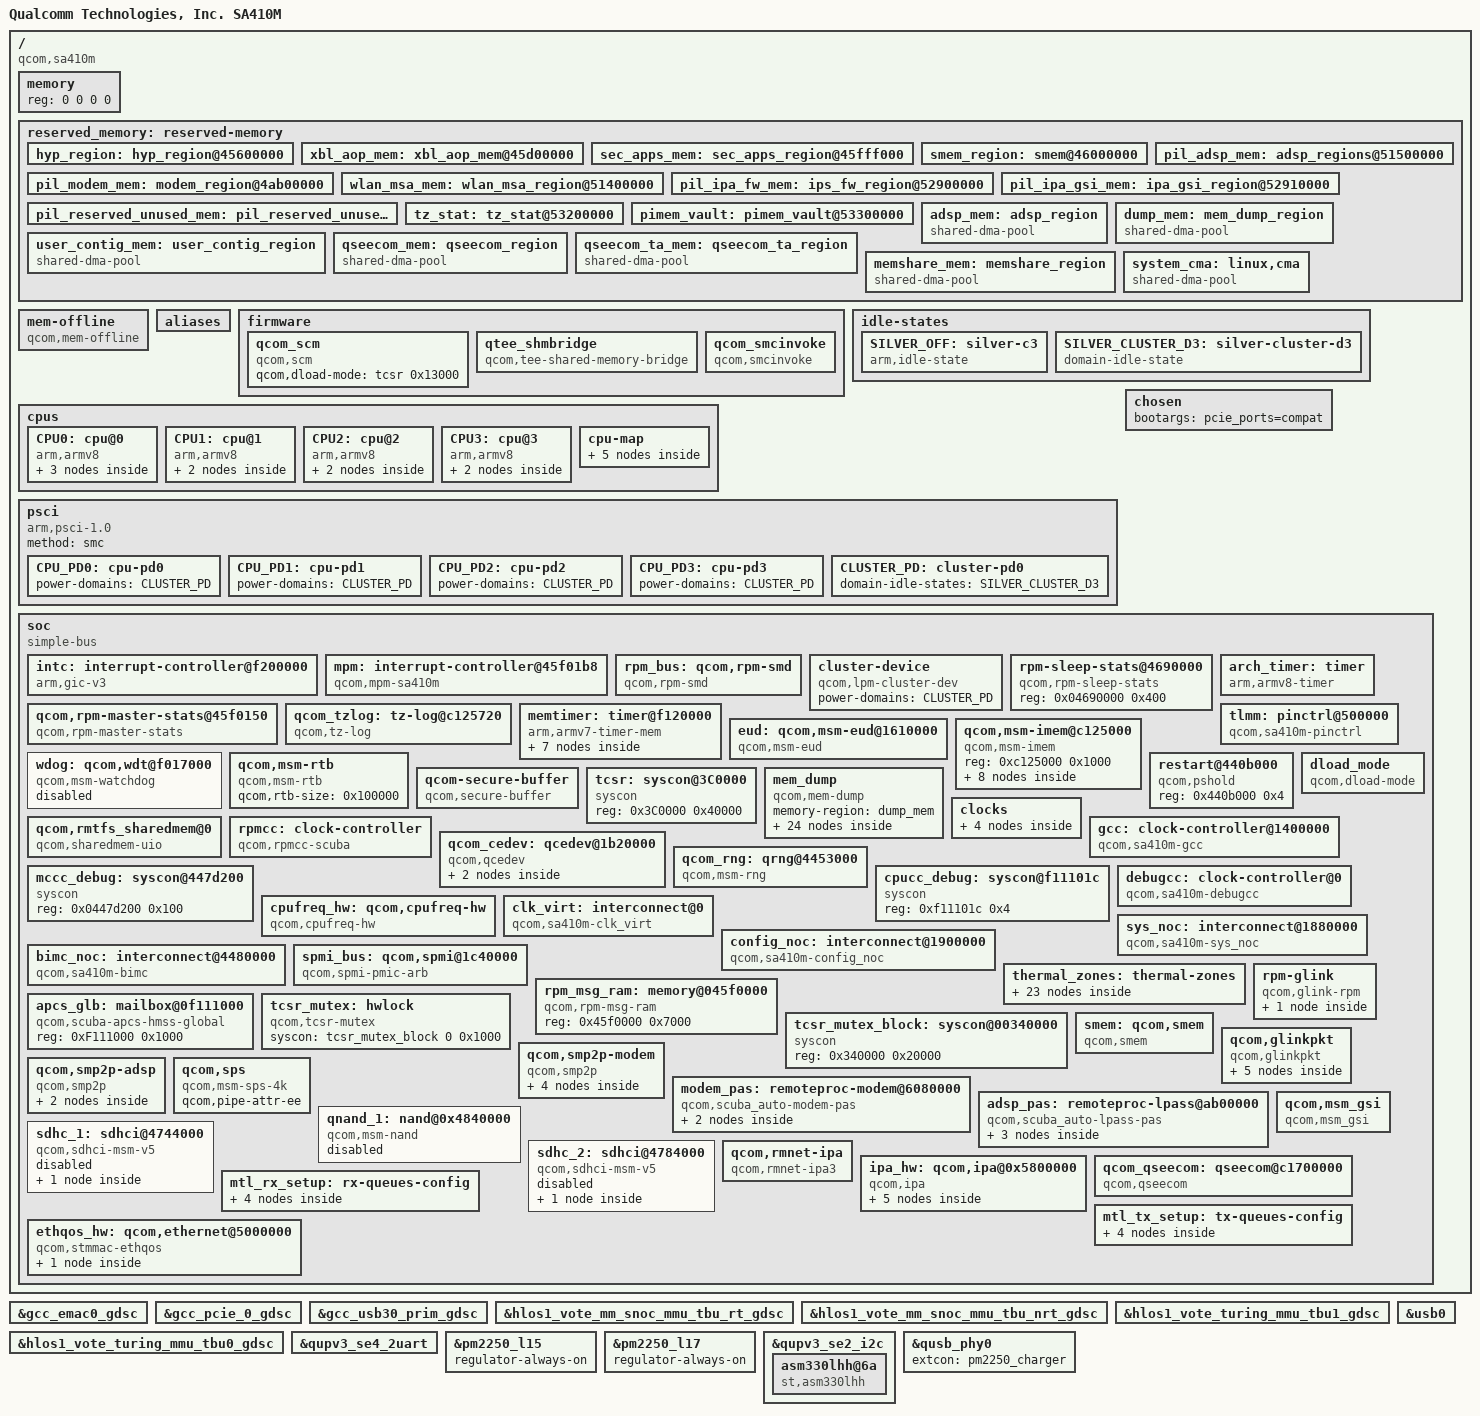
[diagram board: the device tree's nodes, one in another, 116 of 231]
#include <dt-bindings/interconnect/qcom,icc.h>
#include <dt-bindings/interconnect/qcom,sa410m.h>
#include <dt-bindings/interrupt-controller/arm-gic.h>
#include <dt-bindings/gpio/gpio.h>
#include <dt-bindings/clock/qcom,gcc-sa410m.h>
#include <dt-bindings/clock/qcom,rpmcc.h>
#include <dt-bindings/regulator/qcom,rpmh-regulator-levels.h>

/ {
	model = "Qualcomm Technologies, Inc. SA410M";
	compatible = "qcom,sa410m";
	qcom,msm-id = <560 0x10000>;
	interrupt-parent = <&intc>;

	#address-cells = <2>;
	#size-cells = <2>;
	memory { device_type = "memory"; reg = <0 0 0 0>; };

	reserved_memory: reserved-memory { };

	mem-offline {
		compatible = "qcom,mem-offline";
		offline-sizes = <0x1 0x40000000 0x0 0x40000000>,
				<0x1 0xc0000000 0x0 0x80000000>,
				<0x2 0xc0000000 0x1 0x40000000>;
		granule = <512>;
	};

	aliases: aliases {
		serial0 = &qupv3_se4_2uart;
		qpic_nand1 = &qnand_1;
		mmc0 = &sdhc_1; /*SDC1 eMMC slot*/
		mmc1 = &sdhc_2; /* SDC2 SD card slot */
		pci-domain0 = &pcie0;
	};

	firmware: firmware {};

	cpus {
		#address-cells = <2>;
		#size-cells = <0>;

		CPU0: cpu@0 {
			device_type = "cpu";
			compatible = "arm,armv8";
			reg = <0x0 0x0>;
			cpu-idle-states = <&SILVER_OFF>;
			power-domains = <&CPU_PD0>;
			power-domain-names = "psci";
			enable-method = "psci";
			capacity-dmips-mhz = <1024>;
			dynamic-power-coefficient = <100>;
			next-level-cache = <&L2_0>;
			qcom,freq-domain = <&cpufreq_hw 0>;
			qcom,lmh-dcvs = <&lmh_dcvs0>;
			#cooling-cells = <2>;
			L2_0: l2-cache {
				compatible = "arm,arch-cache";
				cache-level = <2>;
			};

			L1_I_0: l1-icache {
				compatible = "arm,arch-cache";
			};

			L1_D_0: l1-dcache {
				compatible = "arm,arch-cache";
			};
		};

		CPU1: cpu@1 {
			device_type = "cpu";
			compatible = "arm,armv8";
			reg = <0x0 0x1>;
			cpu-idle-states = <&SILVER_OFF>;
			power-domains = <&CPU_PD1>;
			power-domain-names = "psci";
			enable-method = "psci";
			capacity-dmips-mhz = <1024>;
			dynamic-power-coefficient = <100>;
			next-level-cache = <&L2_0>;
			qcom,freq-domain = <&cpufreq_hw 0>;
			qcom,lmh-dcvs = <&lmh_dcvs0>;
			#cooling-cells = <2>;

			L1_I_1: l1-icache {
				compatible = "arm,arch-cache";
			};

			L1_D_1: l1-dcache {
				compatible = "arm,arch-cache";
			};
		};

		CPU2: cpu@2 {
			device_type = "cpu";
			compatible = "arm,armv8";
			reg = <0x0 0x2>;
			cpu-idle-states = <&SILVER_OFF>;
			power-domains = <&CPU_PD2>;
			power-domain-names = "psci";
			enable-method = "psci";
			capacity-dmips-mhz = <1024>;
			dynamic-power-coefficient = <100>;
			next-level-cache = <&L2_0>;
			qcom,freq-domain = <&cpufreq_hw 0>;
			qcom,lmh-dcvs = <&lmh_dcvs0>;
			#cooling-cells = <2>;

			L1_I_2: l1-icache {
				compatible = "arm,arch-cache";
			};

			L1_D_2: l1-dcache {
				compatible = "arm,arch-cache";
			};
		};

		CPU3: cpu@3 {
			device_type = "cpu";
			compatible = "arm,armv8";
			reg = <0x0 0x3>;
			cpu-idle-states = <&SILVER_OFF>;
			power-domains = <&CPU_PD3>;
			power-domain-names = "psci";
			enable-method = "psci";
			capacity-dmips-mhz = <1024>;
			dynamic-power-coefficient = <100>;
			next-level-cache = <&L2_0>;
			qcom,freq-domain = <&cpufreq_hw 0>;
			qcom,lmh-dcvs = <&lmh_dcvs0>;
			#cooling-cells = <2>;

			L1_I_3: l1-icache {
				compatible = "arm,arch-cache";
			};

			L1_D_3: l1-dcache {
				compatible = "arm,arch-cache";
			};
		};

		cpu-map {
			cluster0 {
				core0 {
					cpu = <&CPU0>;
				};

				core1 {
					cpu = <&CPU1>;
				};

				core2 {
					cpu = <&CPU2>;
				};

				core3 {
					cpu = <&CPU3>;
				};
			};
		};
	};

	idle-states {
		SILVER_OFF: silver-c3 {  /* C3 */
			compatible = "arm,idle-state";
			idle-state-name = "pc";
			entry-latency-us = <297>;
			exit-latency-us = <324>;
			min-residency-us = <1110>;
			arm,psci-suspend-param = <0x40000003>;
			local-timer-stop;
		};

		SILVER_CLUSTER_D3: silver-cluster-d3 { /* D3 */
			compatible = "domain-idle-state";
			idle-state-name = "pwr-l2-pc";
			entry-latency-us = <800>;
			exit-latency-us = <2118>;
			min-residency-us = <7376>;
			arm,psci-suspend-param = <0x41000043>;
		};
	};

	psci {
		compatible = "arm,psci-1.0";
		method = "smc";

		CPU_PD0: cpu-pd0 {
			#power-domain-cells = <0>;
			power-domains = <&CLUSTER_PD>;
		};

		CPU_PD1: cpu-pd1 {
			#power-domain-cells = <0>;
			power-domains = <&CLUSTER_PD>;
		};

		CPU_PD2: cpu-pd2 {
			#power-domain-cells = <0>;
			power-domains = <&CLUSTER_PD>;
		};

		CPU_PD3: cpu-pd3 {
			#power-domain-cells = <0>;
			power-domains = <&CLUSTER_PD>;
		};

		CLUSTER_PD: cluster-pd0 {
			#power-domain-cells = <0>;
			domain-idle-states = <&SILVER_CLUSTER_D3>;
		};
	};

	chosen {
		bootargs = "pcie_ports=compat";
	};

	soc: soc { };
};

&reserved_memory {
	#address-cells = <2>;
	#size-cells = <2>;
	ranges;

	hyp_region: hyp_region@45600000 {
		no-map;
		reg = <0x0 0x45600000 0x0 0x700000>;
	};

	xbl_aop_mem: xbl_aop_mem@45d00000 {
		no-map;
		reg = <0x0 0x45d00000 0x0 0x200000>;
	};

	sec_apps_mem: sec_apps_region@45fff000 {
		no-map;
		reg = <0x0 0x45fff000 0x0 0x1000>;
	};

	smem_region: smem@46000000 {
		no-map;
		reg = <0x0 0x46000000 0x0 0x200000>;
	};

	pil_modem_mem: modem_region@4ab00000 {
		no-map;
		reg = <0x0 0x4ab00000 0x0 0x6900000>;
	};

	wlan_msa_mem: wlan_msa_region@51400000 {
		no-map;
		reg = <0x0 0x51400000 0x0 0x100000>;
	};

	pil_adsp_mem: adsp_regions@51500000 {
		no-map;
		reg = <0x0 0x51500000 0x0 0x1400000>;
	};

	pil_ipa_fw_mem: ips_fw_region@52900000 {
		no-map;
		reg = <0x0 0x52900000 0x0 0x10000>;
	};

	pil_ipa_gsi_mem: ipa_gsi_region@52910000 {
		no-map;
		reg = <0x0 0x52910000 0x0 0x5000>;
	};

	pil_reserved_unused_mem: pil_reserved_unused_region@52915000 {
		no-map;
		reg = <0x0 0x52915000 0x0 0xEB000>;
	};

	tz_stat: tz_stat@53200000 {
		no-map;
		reg = <0x0 0x53200000 0x0 0x100000>;
	};

	pimem_vault: pimem_vault@53300000 {
		no-map;
		reg = <0x0 0x53300000 0x0 0x1500000>;
	};

	adsp_mem: adsp_region {
		compatible = "shared-dma-pool";
		alloc-ranges = <0 0x00000000 0 0xffffffff>;
		reusable;
		alignment = <0 0x400000>;
		size = <0 0x800000>;
	};

	dump_mem: mem_dump_region {
		compatible = "shared-dma-pool";
		alloc-ranges = <0x0 0x00000000 0x0 0xffffffff>;
		reusable;
		size = <0 0x800000>;
	};

	user_contig_mem: user_contig_region {
		compatible = "shared-dma-pool";
		alloc-ranges = <0x0 0x00000000 0x0 0xffffffff>;
		reusable;
		alignment = <0x0 0x400000>;
		size = <0x0 0x1000000>;
	};

	qseecom_mem: qseecom_region {
		compatible = "shared-dma-pool";
		alloc-ranges = <0x0 0x00000000 0x0 0xffffffff>;
		reusable;
		alignment = <0x0 0x400000>;
		size = <0x0 0x800000>;
	};

	qseecom_ta_mem: qseecom_ta_region {
		compatible = "shared-dma-pool";
		alloc-ranges = <0x0 0x00000000 0x0 0xffffffff>;
		reusable;
		alignment = <0x0 0x400000>;
		size = <0x0 0x400000>;
	};

	memshare_mem: memshare_region {
		compatible = "shared-dma-pool";
		no-map;
		alloc-ranges = <0x0 0x00000000 0x0 0xffffffff>;
		alignment = <0x0 0x100000>;
		size = <0x0 0x800000>;
	};

	/* global autoconfigured region for contiguous allocations */
	system_cma:linux,cma {
		compatible = "shared-dma-pool";
		alloc-ranges = <0x0 0x00000000 0x0 0xffffffff>;
		reusable;
		alignment = <0x0 0x400000>;
		size = <0x0 0x2000000>;
		linux,cma-default;
	};
};

&soc {
	#address-cells = <1>;
	#size-cells = <1>;
	ranges = <0 0 0 0xffffffff>;
	compatible = "simple-bus";

	intc: interrupt-controller@f200000 {
		compatible = "arm,gic-v3";
		#interrupt-cells = <3>;
		interrupt-controller;
		interrupt-parent = <&intc>;
		#redistributor-regions = <1>;
		redistributor-stride = <0x0 0x20000>;
		reg = <0xf200000 0x10000>,	 /* GICD */
			  <0xf300000 0x100000>;	/* GICR * 8 */
		interrupts = <GIC_PPI 9 IRQ_TYPE_LEVEL_HIGH>;
		#gpio-cells = <0>;
	};

	mpm: interrupt-controller@45f01b8 {
		compatible = "qcom,mpm-sa410m", "qcom,mpm";
		reg = <0x45f01b8 0x1000>,
		      <0xf111008 0x4>,  /* MSM_APCS_GCC_BASE 4K */
		      <0xf121000 0x1000>;
		reg-names = "vmpm", "ipc", "timer";
		interrupts = <GIC_SPI 197 IRQ_TYPE_EDGE_RISING>;
		qcom,num-mpm-irqs = <96>;
		interrupt-controller;
		interrupt-parent = <&intc>;
		#interrupt-cells = <2>;
	};

	rpm_bus: qcom,rpm-smd {
		compatible = "qcom,rpm-smd";
		rpm-channel-name = "rpm_requests";
		interrupts = <GIC_SPI 194 IRQ_TYPE_EDGE_RISING>;
		power-domains = <&CLUSTER_PD>;
		rpm-channel-type = <15>; /* SMD_APPS_RPM */
	};

	cluster-device {
		compatible = "qcom,lpm-cluster-dev";
		power-domains = <&CLUSTER_PD>;
	};

	rpm-sleep-stats@4690000 {
		compatible = "qcom,rpm-sleep-stats";
		reg = <0x04690000 0x400>;
	};

	qcom,rpm-master-stats@45f0150 {
		compatible = "qcom,rpm-master-stats";
		reg = <0x45f0150 0x5000>;
		qcom,masters = "APSS", "MPSS", "ADSP", "CDSP", "TZ";
		qcom,master-stats-version = <2>;
		qcom,master-offset = <4096>;
	};

	arch_timer: timer {
		compatible = "arm,armv8-timer";
		interrupts = <GIC_PPI 1 (GIC_CPU_MASK_SIMPLE(8) | IRQ_TYPE_LEVEL_LOW)>,
				 <GIC_PPI 2 (GIC_CPU_MASK_SIMPLE(8) | IRQ_TYPE_LEVEL_LOW)>,
				 <GIC_PPI 3 (GIC_CPU_MASK_SIMPLE(8) | IRQ_TYPE_LEVEL_LOW)>,
				 <GIC_PPI 0 (GIC_CPU_MASK_SIMPLE(8) | IRQ_TYPE_LEVEL_LOW)>;
		clock-frequency = <19200000>;
	};

	qcom_tzlog: tz-log@c125720 {
		compatible = "qcom,tz-log";
		reg = <0xc125720 0x3000>;
		qcom,hyplog-enabled;
		hyplog-address-offset = <0x410>;
		hyplog-size-offset = <0x414>;
	};

	memtimer: timer@f120000 {
		#address-cells = <1>;
		#size-cells = <1>;
		ranges;
		compatible = "arm,armv7-timer-mem";
		reg = <0xf120000 0x1000>;
		clock-frequency = <19200000>;

		frame@f121000 {
			frame-number = <0>;
			interrupts = <GIC_SPI 8 IRQ_TYPE_LEVEL_HIGH>,
					 <GIC_SPI 7 IRQ_TYPE_LEVEL_HIGH>;
			reg = <0xf121000 0x1000>,
				  <0xf122000 0x1000>;
		};

		frame@f123000 {
			frame-number = <1>;
			interrupts = <GIC_SPI 9 IRQ_TYPE_LEVEL_HIGH>;
			reg = <0xf123000 0x1000>;
			status = "disabled";
		};

		frame@f124000 {
			frame-number = <2>;
			interrupts = <GIC_SPI 10 IRQ_TYPE_LEVEL_HIGH>;
			reg = <0xf124000 0x1000>;
			status = "disabled";
		};

		frame@f125000 {
			frame-number = <3>;
			interrupts = <GIC_SPI 11 IRQ_TYPE_LEVEL_HIGH>;
			reg = <0xf125000 0x1000>;
			status = "disabled";
		};

		frame@f126000 {
			frame-number = <4>;
			interrupts = <GIC_SPI 12 IRQ_TYPE_LEVEL_HIGH>;
			reg = <0xf126000 0x1000>;
			status = "disabled";
		};

		frame@f127000 {
			frame-number = <5>;
			interrupts = <GIC_SPI 13 IRQ_TYPE_LEVEL_HIGH>;
			reg = <0xf127000 0x1000>;
			status = "disabled";
		};

		frame@f128000 {
			frame-number = <6>;
			interrupts = <GIC_SPI 14 IRQ_TYPE_LEVEL_HIGH>;
			reg = <0xf128000 0x1000>;
			status = "disabled";
		};
	};

	tlmm: pinctrl@500000 {
			compatible = "qcom,sa410m-pinctrl";
			reg = <0x500000 0x7F000>,
				<0x598000 0xD000>;
			reg-names = "normal" , "extended";
			interrupts = <GIC_SPI 227 IRQ_TYPE_LEVEL_HIGH>;
			gpio-ranges = <&tlmm 0 0 139>;
			gpio-controller;
			#gpio-cells = <2>;
			wakeup-parent = <&mpm>;
			interrupt-controller;
			#interrupt-cells = <2>;
	};

	eud: qcom,msm-eud@1610000 {
		compatible = "qcom,msm-eud";
		interrupt-names = "eud_irq";
		interrupts = <GIC_SPI 189 IRQ_TYPE_LEVEL_HIGH>;
		reg = <0x1610000 0x2000>,
		      <0x1612000 0x1000>,
		      <0x3E5018 0x4>;
		reg-names = "eud_base", "eud_mode_mgr2",
				"eud_tcsr_check_reg";
		qcom,secure-eud-en;
		qcom,eud-tcsr-check-enable;
		qcom,eud-clock-vote-req;
		clocks = <&gcc GCC_AHB2PHY_USB_CLK>;
		clock-names = "eud_ahb2phy_clk";
		status = "ok";
	};

	qcom,msm-imem@c125000 {
		compatible = "qcom,msm-imem";
		reg = <0xc125000 0x1000>;
		ranges = <0x0 0xc125000 0x1000>;
		#address-cells = <1>;
		#size-cells = <1>;

		mem_dump_table@10 {
			compatible = "qcom,msm-imem-mem_dump_table";
			reg = <0x10 0x8>;
		};

		dload_type@1c {
			compatible = "qcom,msm-imem-dload-type";
			reg = <0x1c 0x4>;
		};

		restart_reason@65c {
			compatible = "qcom,msm-imem-restart_reason";
			reg = <0x65c 0x4>;
		};

		boot_stats@6b0 {
			compatible = "qcom,msm-imem-boot_stats";
			reg = <0x6b0 0x20>;
		};

		kaslr_offset@6d0 {
			compatible = "qcom,msm-imem-kaslr_offset";
			reg = <0x6d0 0xc>;
		};

		pil@94c {
			compatible = "qcom,pil-reloc-info";
			reg = <0x94c 0xc8>;
		};

		pil@6dc {
			compatible = "qcom,msm-imem-pil-disable-timeout";
			reg = <0x6dc 0x4>;
		};

		diag_dload@c8 {
			compatible = "qcom,msm-imem-diag-dload";
			reg = <0xc8 0xc8>;
		};
	};

	wdog: qcom,wdt@f017000 {
		compatible = "qcom,msm-watchdog";
		reg = <0xf017000 0x1000>;
		reg-names = "wdt-base";
		interrupts = <GIC_SPI 3 IRQ_TYPE_EDGE_RISING>,
				<GIC_SPI 4 IRQ_TYPE_LEVEL_HIGH>;
		status="disabled";
	};

	qcom,msm-rtb {
		compatible = "qcom,msm-rtb";
		qcom,rtb-size = <0x100000>;
	};

	restart@440b000 {
		compatible = "qcom,pshold";
		reg = <0x440b000 0x4>;
	};

	dload_mode {
		compatible = "qcom,dload-mode";
	};

	qcom-secure-buffer {
		compatible = "qcom,secure-buffer";
	};

	tcsr: syscon@3C0000 {
		compatible = "syscon";
		reg = <0x3C0000 0x40000>;
	};

	mem_dump {
		compatible = "qcom,mem-dump";
		memory-region = <&dump_mem>;

		c0_context {
			qcom,dump-size = <0x800>;
			qcom,dump-id = <0x0>;
		};

		c1_context {
			qcom,dump-size = <0x800>;
			qcom,dump-id = <0x1>;
		};

		c2_context {
			qcom,dump-size = <0x800>;
			qcom,dump-id = <0x2>;
		};

		c3_context {
			qcom,dump-size = <0x800>;
			qcom,dump-id = <0x3>;
		};

		l1_icache0 {
			qcom,dump-size = <0x9040>;
			qcom,dump-id = <0x60>;
		};

		l1_icache1 {
			qcom,dump-size = <0x9040>;
			qcom,dump-id = <0x61>;
		};

		l1_icache2 {
			qcom,dump-size = <0x9040>;
			qcom,dump-id = <0x62>;
		};

		l1_icache3 {
			qcom,dump-size = <0x9040>;
			qcom,dump-id = <0x63>;
		};

		l1_dcache0 {
			qcom,dump-size = <0x9040>;
			qcom,dump-id = <0x80>;
		};

		l1_dcache1 {
			qcom,dump-size = <0x9040>;
			qcom,dump-id = <0x81>;
		};

		l1_dcache2 {
			qcom,dump-size = <0x9040>;
			qcom,dump-id = <0x82>;
		};

		l1_dcache3 {
			qcom,dump-size = <0x9040>;
			qcom,dump-id = <0x83>;
		};

		l2_tlb0 {
			qcom,dump-size = <0x2000>;
			qcom,dump-id = <0x120>;
		};

		l2_tlb1 {
			qcom,dump-size = <0x2000>;
			qcom,dump-id = <0x121>;
		};

		l2_tlb2 {
			qcom,dump-size = <0x2000>;
			qcom,dump-id = <0x122>;
		};

		l2_tlb3 {
			qcom,dump-size = <0x2000>;
			qcom,dump-id = <0x123>;
		};

		spm_reg {
			qcom,dump-size = <0x400>;
			qcom,dump-id = <0x164>;
		};

		rpm_sw {
			qcom,dump-size = <0x28000>;
			qcom,dump-id = <0xea>;
		};

		pmic {
			qcom,dump-size = <0x40000>;
			qcom,dump-id = <0xe4>;
		};

		fcm {
			qcom,dump-size = <0x8400>;
			qcom,dump-id = <0xee>;
		};

		tmc_etf {
			qcom,dump-size = <0x8000>;
			qcom,dump-id = <0xf0>;
		};

		etr_reg {
			qcom,dump-size = <0x1000>;
			qcom,dump-id = <0x100>;
		};

		etf_reg {
			qcom,dump-size = <0x1000>;
			qcom,dump-id = <0x101>;
		};

		misc_data {
			qcom,dump-size = <0x1000>;
			qcom,dump-id = <0xe8>;
		};
	};

	qcom,rmtfs_sharedmem@0 {
		compatible = "qcom,sharedmem-uio";
		reg = <0x0 0x280000>;
		reg-names = "rmtfs";
		qcom,client-id = <0x00000001>;
		qcom,vm-nav-path;
	};

	clocks {
		xo_board: xo-board {
			compatible = "fixed-clock";
			clock-frequency = <38400000>;
			clock-output-names = "xo_board";
			#clock-cells = <0>;
		};

		sleep_clk: sleep-clk {
			compatible = "fixed-clock";
			clock-frequency = <32000>;
			clock-output-names = "chip_sleep_clk";
			#clock-cells = <0>;
		};

		pcie_0_pipe_clk: pcie_0_pipe_clk {
			compatible = "fixed-clock";
			clock-frequency = <1000>;
			clock-output-names = "pcie_0_pipe_clk";
			#clock-cells = <0>;
		};

		usb3_phy_wrapper_gcc_usb30_pipe_clk: usb3_phy_wrapper_gcc_usb30_pipe_clk {
			compatible = "fixed-clock";
			clock-frequency = <1000>;
			clock-output-names = "usb3_phy_wrapper_gcc_usb30_pipe_clk";
			#clock-cells = <0>;
		};
	};

	rpmcc: clock-controller {
		compatible = "qcom,rpmcc-scuba";
		#clock-cells = <1>;
	};

	gcc: clock-controller@1400000 {
		compatible = "qcom,sa410m-gcc", "syscon";
		reg = <0x1400000 0x1f0000>;
		reg-name = "cc_base";
		vdd_cx-supply = <&VDD_CX_LEVEL>;
		clocks = <&rpmcc RPM_SMD_XO_CLK_SRC>,
			 <&rpmcc RPM_SMD_XO_A_CLK_SRC>,
			<&pcie_0_pipe_clk>,
			<&sleep_clk>,
			<&usb3_phy_wrapper_gcc_usb30_pipe_clk>;
		clock-names = "bi_tcxo",
			"bi_tcxo_ao",
			"pcie_0_pipe_clk",
			"sleep_clk",
			"usb3_phy_wrapper_gcc_usb30_pipe_clk";
		#clock-cells = <1>;
		#reset-cells = <1>;
	};

	qcom_cedev: qcedev@1b20000 {
		compatible = "qcom,qcedev";
		reg = <0x1b20000 0x20000>,
			<0x1b04000 0x24000>;
		reg-names = "crypto-base","crypto-bam-base";
		interrupts = <GIC_SPI 247 IRQ_TYPE_LEVEL_HIGH>;
		qcom,bam-pipe-pair = <2>;
		qcom,ce-hw-instance = <0>;
		qcom,ce-device = <0>;
		qcom,ce-hw-shared;
		qcom,bam-ee = <0>;
		qcom,smmu-s1-enable;
		qcom,no-clock-support;
		interconnect-names = "data_path";
		interconnects = <&sys_noc MASTER_CRYPTO_CORE0 &bimc_noc SLAVE_EBI_CH0>;
		iommus = <&apps_smmu 0x0084 0x0011>,
				<&apps_smmu 0x0092 0x00>,
				<&apps_smmu 0x0086 0x0011>;
		qcom,iommu-dma = "atomic";
		dma-coherent;

		qcom_cedev_ns_cb {
			compatible = "qcom,qcedev,context-bank";
			label = "ns_context";
			iommus = <&apps_smmu 0x0086 0x0011>,
				<&apps_smmu 0x0092 0x00>,
				<&apps_smmu 0x0098 0x0001>;
			dma-coherent;
		};

		qcom_cedev_s_cb {
			compatible = "qcom,qcedev,context-bank";
			label = "secure_context";
			iommus = <&apps_smmu 0x093 0x000>,
				 <&apps_smmu 0x09c 0x001>,
				 <&apps_smmu 0x09d 0x001>,
				 <&apps_smmu 0x09E 0x000>;
			qcom,iommu-vmid = <0x9>;
			qcom,secure-context-bank;
		};
	};

	qcom_rng: qrng@4453000 {
		compatible = "qcom,msm-rng";
		reg = <0x4453000 0x1000>;
		qcom,no-qrng-config;
		qcom,no-clock-support;
	};

	mccc_debug: syscon@447d200 {
		compatible = "syscon";
		reg = <0x0447d200 0x100>;
	};

	cpucc_debug: syscon@f11101c {
		compatible = "syscon";
		reg = <0xf11101c 0x4>;
	};

	debugcc: clock-controller@0 {
		compatible = "qcom,sa410m-debugcc";
		qcom,gcc = <&gcc>;
		qcom,mccc = <&mccc_debug>;
		qcom,cpucc = <&cpucc_debug>;
		clock-names = "xo_clk_src";
		clocks = <&rpmcc RPM_SMD_XO_CLK_SRC>, <&gcc 0>;
		#clock-cells = <1>;
	};

	cpufreq_hw: qcom,cpufreq-hw {
		compatible = "qcom,cpufreq-hw";
		reg = <0xf521000 0x1400>;
		reg-names = "freq-domain0";
		clocks = <&rpmcc RPM_SMD_XO_CLK_SRC>, <&gcc GPLL0>;
		clock-names = "xo", "alternate";
		#freq-domain-cells = <1>;
	};

	clk_virt: interconnect@0 {
		compatible = "qcom,sa410m-clk_virt";
		qcom,keepalive;
		#interconnect-cells = <1>;
		clock-names = "bus", "bus_a";
		clocks = <&rpmcc RPM_SMD_QUP_CLK>,
			<&rpmcc RPM_SMD_QUP_A_CLK>;
	};

	sys_noc: interconnect@1880000 {
		reg = <0x1880000 0x5e080>;
		compatible = "qcom,sa410m-sys_noc";
		qcom,keepalive;
		#interconnect-cells = <1>;
		clock-names = "bus", "bus_a";
		clocks = <&rpmcc RPM_SMD_SNOC_CLK>,
			<&rpmcc RPM_SMD_SNOC_A_CLK>;
	};

	config_noc: interconnect@1900000 {
		reg = <0x01900000 0x9200>;
		compatible = "qcom,sa410m-config_noc";
		qcom,keepalive;
		#interconnect-cells = <1>;
		clock-names = "bus", "bus_a";
		clocks = <&rpmcc RPM_SMD_CNOC_CLK>,
			<&rpmcc RPM_SMD_CNOC_A_CLK>;
	};

	bimc_noc: interconnect@4480000 {
		reg = <0x4480000 0x80000>;
		compatible = "qcom,sa410m-bimc";
		qcom,util-factor = <153>;
		qcom,keepalive;
		#interconnect-cells = <1>;
		clock-names = "bus", "bus_a";
		clocks = <&rpmcc RPM_SMD_BIMC_CLK>,
			<&rpmcc RPM_SMD_BIMC_A_CLK>;
	};

	spmi_bus: qcom,spmi@1c40000 {
		compatible = "qcom,spmi-pmic-arb";
		reg = <0x1c40000 0x1100>,
			<0x1e00000 0x2000000>,
			<0x3e00000 0x100000>,
			<0x3f00000 0xa0000>,
			<0x1c0a000 0x26000>;
		reg-names = "core", "chnls", "obsrvr", "intr", "cnfg";
		interrupt-names = "periph_irq";
		interrupts-extended = <&mpm 86 IRQ_TYPE_LEVEL_HIGH>;
		qcom,ee = <0>;
		qcom,channel = <0>;
		#address-cells = <2>;
		#size-cells = <0>;
		interrupt-controller;
		#interrupt-cells = <4>;
		cell-index = <0>;
	};

	thermal_zones: thermal-zones { };

	rpm_msg_ram: memory@045f0000 {
		compatible = "qcom,rpm-msg-ram";
		reg = <0x45f0000 0x7000>;
	};

	apcs_glb: mailbox@0f111000 {
		compatible = "qcom,scuba-apcs-hmss-global";
		reg = <0xF111000 0x1000>;

		#mbox-cells = <1>;
	};

	rpm-glink {
		compatible = "qcom,glink-rpm";
		interrupts = <GIC_SPI 194 IRQ_TYPE_EDGE_RISING>;
		qcom,rpm-msg-ram = <&rpm_msg_ram>;
		mboxes = <&apcs_glb 0>;

		qcom,rpm_glink_ssr {
			qcom,glink-channels = "glink_ssr";
			// qcom,notify-edges = <&glink_adsp>;
		};
	};

	tcsr_mutex_block: syscon@00340000 {
		compatible = "syscon";
		reg = <0x340000 0x20000>;
	};

	tcsr_mutex: hwlock {
		compatible = "qcom,tcsr-mutex";
		syscon = <&tcsr_mutex_block 0 0x1000>;
		#hwlock-cells = <1>;
	};

	smem: qcom,smem {
		compatible = "qcom,smem";
		memory-region = <&smem_region>;
		hwlocks = <&tcsr_mutex 3>;
	};

	qcom,glinkpkt {
		compatible = "qcom,glinkpkt";

		qcom,glinkpkt-at-mdm0 {
			qcom,glinkpkt-edge = "mpss";
			qcom,glinkpkt-ch-name = "DS";
			qcom,glinkpkt-dev-name = "at_mdm0";
		};

		qcom,glinkpkt-data40-cntl {
			qcom,glinkpkt-edge = "mpss";
			qcom,glinkpkt-ch-name = "DATA40_CNTL";
			qcom,glinkpkt-dev-name = "smdcntl8";
		};

		qcom,glinkpkt-data1 {
			qcom,glinkpkt-edge = "mpss";
			qcom,glinkpkt-ch-name = "DATA1";
			qcom,glinkpkt-dev-name = "smd7";
		};

		qcom,glinkpkt-data4 {
			qcom,glinkpkt-edge = "mpss";
			qcom,glinkpkt-ch-name = "DATA4";
			qcom,glinkpkt-dev-name = "smd8";
		};

		qcom,glinkpkt-data11 {
			qcom,glinkpkt-edge = "mpss";
			qcom,glinkpkt-ch-name = "DATA11";
			qcom,glinkpkt-dev-name = "smd11";
		};
	};

	qcom,smp2p-modem {
		compatible = "qcom,smp2p";
		qcom,smem = <435>, <428>;
		interrupts = <GIC_SPI 70 IRQ_TYPE_EDGE_RISING>;
		mboxes = <&apcs_glb 14>;
		qcom,local-pid = <0>;
		qcom,remote-pid = <1>;

		modem_smp2p_out: master-kernel {
			qcom,entry-name = "master-kernel";
			#qcom,smem-state-cells = <1>;
		};

		modem_smp2p_in: slave-kernel {
			qcom,entry-name = "slave-kernel";
			interrupt-controller;
			#interrupt-cells = <2>;
		};

		smp2p_ipa_1_out: qcom,smp2p-ipa-1-out {
			qcom,entry-name = "ipa";
			#qcom,smem-state-cells = <1>;
		};

		/* ipa - inbound entry from mss */
		smp2p_ipa_1_in: qcom,smp2p-ipa-1-in {
			qcom,entry-name = "ipa";
			interrupt-controller;
			#interrupt-cells = <2>;
		};
	};

	qcom,smp2p-adsp {
		compatible = "qcom,smp2p";
		qcom,smem = <443>, <429>;
		interrupts = <GIC_SPI 279 IRQ_TYPE_EDGE_RISING>;
		mboxes = <&apcs_glb 10>;
		qcom,local-pid = <0>;
		qcom,remote-pid = <2>;

		adsp_smp2p_out: master-kernel {
			qcom,entry-name = "master-kernel";
			#qcom,smem-state-cells = <1>;
		};

		adsp_smp2p_in: slave-kernel {
			qcom,entry-name = "slave-kernel";
			interrupt-controller;
			#interrupt-cells = <2>;
		};
	};

	qcom,sps {
		compatible = "qcom,msm-sps-4k";
		qcom,pipe-attr-ee;
	};

	modem_pas: remoteproc-modem@6080000 {
		compatible = "qcom,scuba_auto-modem-pas";
		reg = <0x6080000 0x100>;

		clocks = <&rpmcc RPM_SMD_XO_CLK_SRC>;
		clock-names = "xo";
		status = "ok";

		cx-supply = <&VDD_CX_LEVEL>;
		cx-uV-uA = <RPMH_REGULATOR_LEVEL_TURBO 100000>;
		reg-names = "vdd_cx";

		memory-region = <&pil_modem_mem>;

		/* Inputs from mss */
		interrupts-extended = <&intc 0 307 1>,
						<&modem_smp2p_in 0 0>,
						<&modem_smp2p_in 2 0>,
						<&modem_smp2p_in 1 0>,
						<&modem_smp2p_in 3 0>,
						<&modem_smp2p_in 7 0>;

		interrupt-names = "wdog",
						"fatal",
						"handover",
						"ready",
						"stop-ack",
						"shutdown-ack";

		/* Outputs to mss */
		qcom,smem-states = <&modem_smp2p_out 0>;
		qcom,smem-state-names = "stop";

		glink_modem: glink-edge {
			qcom,remote-pid = <1>;
			transport = "smem";
			mboxes = <&apcs_glb 12>;
			mbox-names = "mpss_smem";
			interrupts = <GIC_SPI 68 IRQ_TYPE_EDGE_RISING>;

			label = "modem";
			qcom,glink-label = "mpss";

			qcom,modem_qrtr {
				qcom,glink-channels = "IPCRTR";
				qcom,low-latency;
				qcom,intents = <0x800  5
						0x2000 3
						0x4400 2>;
			};
		};
	};

	adsp_pas: remoteproc-lpass@ab00000 {
		compatible = "qcom,scuba_auto-lpass-pas";
		reg = <0xab00000 0x00100>;
		status = "ok";

		clocks = <&rpmcc RPM_SMD_XO_CLK_SRC>;
		clock-names = "xo";
		qcom,proxy-clock-names = "xo";

		x-supply = <&VDD_LPI_CX_LEVEL>;
		cx-uV-uA = <RPMH_REGULATOR_LEVEL_TURBO 0>;
		mx-supply = <&VDD_LPI_MX_LEVEL>;
		mx-uV-uA = <RPMH_REGULATOR_LEVEL_TURBO 0>;
		proxy-reg-names = "vdd_lpi_cx", "vdd_lpi_mx";

		memory-region = <&pil_adsp_mem>;

		/* Inputs from lpass */
		interrupts-extended = <&intc 0 282 IRQ_TYPE_EDGE_RISING>,
					<&adsp_smp2p_in 0 0>,
					<&adsp_smp2p_in 2 0>,
					<&adsp_smp2p_in 1 0>,
					<&adsp_smp2p_in 3 0>;

		interrupt-names = "wdog",
				  "fatal",
				  "handover",
				  "ready",
				  "stop-ack";

		/* Outputs to lpass */
		qcom,smem-states = <&adsp_smp2p_out 0>;
		qcom,smem-state-names = "stop";

		glink_adsp: glink-edge {
			qcom,remote-pid = <2>;
			transport = "smem";
			mboxes = <&apcs_glb 8>;
			mbox-names = "adsp_smem";
			interrupts = <GIC_SPI 277 IRQ_TYPE_EDGE_RISING>;

			label = "adsp";
			qcom,glink-label = "lpass";

			qcom,adsp_qrtr {
					qcom,glink-channels = "IPCRTR";
					qcom,low-latency;
					qcom,intents = <0x800  5
							0x2000 3
							0x4400 2>;
			};

			qcom,apr_tal_rpmsg {
					qcom,glink-channels = "apr_audio_svc";
					qcom,intents = <0x200 20>;
			};
		};
	};

	qnand_1: nand@0x4840000 {
		compatible = "qcom,msm-nand";
		reg =   <0x4840000 0x1000>,
			<0x4844000 0x1c000>;
		reg-names =     "nand_phys",
				"bam_phys";
		qcom,reg-adjustment-offset = <0x4000>;
		interrupts = <GIC_SPI 217 IRQ_TYPE_LEVEL_HIGH>;
		interrupt-names = "bam_irq";
		clock-names = "core_clk";
		clocks = <&rpmcc RPM_SMD_QPIC_CLK>;

		interconnects = <&sys_noc MASTER_QPIC &bimc_noc SLAVE_EBI_CH0>;
		interconnect-names = "nand-ddr";
		qcom,msm-bus,name = "qpic_nand";
		qcom,msm-bus,num-cases = <2>;
		qcom,msm-bus,num-paths = <1>;
		qcom,msm-bus,vectors-KBps =
			<0 0>,
		/* Voting for max b/w on PNOC bus for now */
			<1057800 725760>;

		iommus = <&apps_smmu 0x100 0x3>;
		qcom,iommu-dma = "bypass";
		status = "disabled";
	};

	sdhc_1: sdhci@4744000 {
		status = "disabled";

		compatible = "qcom,sdhci-msm-v5";
		reg = <0x04744000 0x1000>, <0x04745000 0x1000>;
		reg-names = "hc", "cqhci";

		interrupts = <GIC_SPI 348 IRQ_TYPE_LEVEL_HIGH>,
				<GIC_SPI 352 IRQ_TYPE_LEVEL_HIGH>;
		interrupt-names = "hc_irq", "pwr_irq";

		bus-width = <8>;
		non-removable;
		supports-cqe;

		no-sd;
		no-sdio;
		qcom,restore-after-cx-collapse;

		mmc-ddr-1_8v;
		mmc-hs200-1_8v;
		mmc-hs400-1_8v;
		mmc-hs400-enhanced-strobe;

		cap-mmc-hw-reset;

		clocks = <&gcc GCC_SDCC1_APPS_CLK>,
			<&gcc GCC_SDCC1_AHB_CLK>;
		clock-names = "core", "iface";


		/* DLL HSR settings. Refer go/hsr - <Target> DLL settings */
		qcom,dll-hsr-list = <0x000f642c 0x0 0x0 0x00010800 0x80040868>;

		/* Add dt entry for gcc hw reset */
		//resets = <&gcc GCC_EMMC_BCR>;
		//reset-names = "core_reset";

		iommus = <&apps_smmu 0xC0 0x0>;
		qcom,iommu-dma = "bypass";

		qos0 {
			mask = <0x0f>;
			vote = <44>;
		};
	};

	sdhc_2: sdhci@4784000 {
		status = "disabled";

		compatible = "qcom,sdhci-msm-v5";
		reg = <0x04784000 0x1000>;
		reg-names = "hc";

		interrupts = <GIC_SPI 350 IRQ_TYPE_LEVEL_HIGH>,
				<GIC_SPI 353 IRQ_TYPE_LEVEL_HIGH>;
		interrupt-names = "hc_irq", "pwr_irq";

		bus-width = <4>;
		no-sdio;
		no-mmc;
		qcom,restore-after-cx-collapse;

		clocks = <&gcc GCC_SDCC2_AHB_CLK>,
			<&gcc GCC_SDCC2_APPS_CLK>;
		clock-names = "iface", "core";

		/* DLL HSR settings. Refer go/hsr - <Target> DLL settings */
		qcom,dll-hsr-list = <0x0007642C 0x0 0x0
					0x81800000 0x80040868>;


		iommus = <&apps_smmu 0xA0 0x0>;
		qcom,iommu-dma = "bypass";

		qos0 {
			mask = <0x0f>;
			vote = <44>;
		};
	};

	qcom,msm_gsi {
		compatible = "qcom,msm_gsi";
	};

	qcom,rmnet-ipa {
		compatible = "qcom,rmnet-ipa3";
		qcom,rmnet-ipa-ssr;
		qcom,ipa-platform-type-msm;
		qcom,ipa-advertise-sg-support;
		qcom,ipa-napi-enable;
	};

	ipa_hw: qcom,ipa@0x5800000 {
		compatible = "qcom,ipa";
		reg = <0x5800000 0x34000>,
			<0x5804000 0x28000>;
		reg-names = "ipa-base", "gsi-base";
		interrupts = <GIC_SPI 257 IRQ_TYPE_LEVEL_HIGH>, <GIC_SPI 259 IRQ_TYPE_LEVEL_HIGH>;
		interrupt-names = "ipa-irq", "gsi-irq";
		qcom,ipa-hw-ver = <16>; /* IPA core version = IPAv4.2 */
		qcom,ipa-hw-mode = <0>;
		qcom,platform-type = <0>; /* MDM platform */
		qcom,ee = <0>;
		qcom,use-ipa-tethering-bridge;
		qcom,modem-cfg-emb-pipe-flt;
		qcom,use-xbl-boot;
		qcom,ipa-wdi2;
		qcom,ipa-wdi2_over_gsi;
		qcom,ipa-endp-delay-wa;
		qcom,use-ipa-pm;
		qcom,arm-smmu;
		qcom,smmu-fast-map;
		qcom,use-64-bit-dma-mask;
		qcom,ipa-fltrt-not-hashable;
		qcom,skip-ieob-mask-wa;
		qcom,msm-bus,name = "ipa";
		qcom,use-gsi-ipa-fw = "ipa_fws";
		clocks = <&rpmcc RPM_SMD_IPA_CLK>;
		clock-names = "core_clk";
		qcom,max_num_smmu_cb = <3>;
		qcom,interconnect,num-cases = <5>;
		qcom,interconnect,num-paths = <3>;
		interconnects = <&sys_noc MASTER_IPA &bimc_noc SLAVE_EBI_CH0>,
				<&sys_noc MASTER_IPA &sys_noc SLAVE_OCIMEM>,
				<&bimc_noc MASTER_AMPSS_M0 &config_noc SLAVE_IPA_CFG>;
		interconnect-names = "ipa_to_ebi1", "ipa_to_imem", "appss_to_ipa";
		/* No vote */
		qcom,no-vote =
		<0 0 0 0 0 0>;

		/* SVS2 */
		qcom,svs2 =
		<80000 465000 80000 68570 80000 30>;

		/* SVS */
		qcom,svs =
		<80000 2000000 80000 267461 80000 109890>;

		/* NOMINAL */
		qcom,nominal =
		<206000 4000000 206000 712961 206000 491520>;

		/* TURBO */
		qcom,turbo =
		<206000 5598900 206000 1436481 206000 491520>;
		qcom,throughput-threshold = <310 600 1000>;
		qcom,scaling-exceptions = <>;

		/* smp2p information */
		qcom,smp2p_map_ipa_1_out {
			compatible = "qcom,smp2p-map-ipa-1-out";
			qcom,smem-states = <&smp2p_ipa_1_out 0>;
			qcom,smem-state-names = "ipa-smp2p-out";
		};

		qcom,smp2p_map_ipa_1_in {
			compatible = "qcom,smp2p-map-ipa-1-in";
			interrupts-extended = <&smp2p_ipa_1_in 0 0>;
			interrupt-names = "ipa-smp2p-in";
		};

		ipa_smmu_ap: ipa_smmu_ap {
			compatible = "qcom,ipa-smmu-ap-cb";
			iommus = <&apps_smmu 0x0140 0x0>;
			qcom,iommu-dma-addr-pool = <0x10000000 0x30000000>;
			/* modem tables in IMEM */
			qcom,additional-mapping = <0x0c123000 0x0c123000 0x2000>;
			qcom,iommu-dma = "fastmap";
			qcom,iommu-geometry = <0 0xB0000000>;
		};

		ipa_smmu_wlan: ipa_smmu_wlan {
			compatible = "qcom,ipa-smmu-wlan-cb";
			iommus = <&apps_smmu 0x141 0x0>;
			/* ipa-uc ram */
			qcom,iommu-dma = "atomic";
		};

		ipa_smmu_uc: ipa_smmu_uc {
			compatible = "qcom,ipa-smmu-uc-cb";
			iommus = <&apps_smmu 0x0142 0x0>;
			qcom,iommu-dma-addr-pool = <0x40400000 0x1fc00000>;
		};
	};

	qcom_qseecom: qseecom@c1700000 {
		compatible = "qcom,qseecom";
		memory-region = <&qseecom_mem>;
		qseecom_mem = <&qseecom_mem>;
		qseecom_ta_mem = <&qseecom_ta_mem>;
		user_contig_mem = <&user_contig_mem>;
		qcom,hlos-num-ce-hw-instances = <1>;
		qcom,hlos-ce-hw-instance = <0>;
		qcom,qsee-ce-hw-instance = <0>;
		qcom,disk-encrypt-pipe-pair = <2>;
		qcom,no-clock-support;
		qcom,appsbl-qseecom-support;
		qcom,commonlib64-loaded-by-uefi;
		qcom,qsee-reentrancy-support = <2>;
	};

	mtl_rx_setup: rx-queues-config {
		snps,rx-queues-to-use = <4>;
		snps,rx-sched-sp;

		queue0 {
			snps,dcb-algorithm;
			snps,map-to-dma-channel = <0x0>;
			snps,route-up;
			snps,priority = <0x1>;
		};

		queue1 {
			snps,dcb-algorithm;
			snps,map-to-dma-channel = <0x1>;
			snps,route-ptp;
		};

		queue2 {
			snps,avb-algorithm;
			snps,map-to-dma-channel = <0x2>;
			snps,route-avcp;
		};

		queue3 {
			snps,avb-algorithm;
			snps,map-to-dma-channel = <0x3>;
			snps,priority = <0xC>;
		};
	};

	mtl_tx_setup: tx-queues-config {
		snps,tx-queues-to-use = <4>;
		snps,tx-sched-sp;
		queue0 {
			snps,dcb-algorithm;
		};

		queue1 {
			snps,dcb-algorithm;
		};

		queue2 {
			snps,avb-algorithm;
			snps,send_slope = <0x1000>;
			snps,idle_slope = <0x1000>;
			snps,high_credit = <0x3E800>;
			snps,low_credit = <0xFFC18000>;
		};

		queue3 {
			snps,avb-algorithm;
			snps,send_slope = <0x1000>;
			snps,idle_slope = <0x1000>;
			snps,high_credit = <0x3E800>;
			snps,low_credit = <0xFFC18000>;
		};
	};

	ethqos_hw: qcom,ethernet@5000000 {
		compatible = "qcom,stmmac-ethqos", "snps,dwmac-4.20a";
		reg = <0x5000000 0x10000>,
			<0x5016000 0x100>,
			<0x500000 0x100000>;
		reg-names = "stmmaceth", "rgmii", "tlmm-central-base";
		interrupts-extended = <&intc 0 271 4>, <&intc 0 419 4>,
			<&tlmm 137 2>;
		interrupt-names = "macirq", "eth_lpi",
			"phy-intr";

		vreg_emac_phy-supply =  <&vreg_emac_phy>;
		vreg_rgmii_io_pads-supply = <&vreg_rgmii_io_pads>;
		gdsc_emac-supply = <&gcc_emac0_gdsc>;

		clocks = <&gcc GCC_EMAC0_AXI_CLK>,
			<&gcc GCC_EMAC0_SLV_AHB_CLK>,
			<&gcc GCC_EMAC0_PTP_CLK>,
			<&gcc GCC_EMAC0_RGMII_CLK>;
		clock-names = "stmmaceth", "pclk", "ptp_ref", "rgmii";

		snps,ptp-ref-clk-rate = <230400000>;
		snps,ptp-req-clk-rate = <125000000>;

		pinctrl-names = "dev-emac-mdc",
			"dev-emac-mdio",
			"dev-emac-rgmii_txd0_state",
			"dev-emac-rgmii_txd1_state",
			"dev-emac-rgmii_txd2_state",
			"dev-emac-rgmii_txd3_state",
			"dev-emac-rgmii_txc_state",
			"dev-emac-rgmii_tx_ctl_state",
			"dev-emac-rgmii_rxd0_state",
			"dev-emac-rgmii_rxd1_state",
			"dev-emac-rgmii_rxd2_state",
			"dev-emac-rgmii_rxd3_state",
			"dev-emac-rgmii_rxc_state",
			"dev-emac-rgmii_rx_ctl_state",
			"dev-emac-phy-vreg",
			"dev-emac-rgmii-vreg";

		pinctrl-0 = <&emac_mdc>;
		pinctrl-1 = <&emac_mdio>;

		pinctrl-2 = <&emac_rgmii_txd0>;
		pinctrl-3 = <&emac_rgmii_txd1>;
		pinctrl-4 = <&emac_rgmii_txd2>;
		pinctrl-5 = <&emac_rgmii_txd3>;
		pinctrl-6 = <&emac_rgmii_txc>;
		pinctrl-7 = <&emac_rgmii_tx_ctl>;

		pinctrl-8 = <&emac_rgmii_rxd0>;
		pinctrl-9 = <&emac_rgmii_rxd1>;
		pinctrl-10 = <&emac_rgmii_rxd2>;
		pinctrl-11 = <&emac_rgmii_rxd3>;
		pinctrl-12 = <&emac_rgmii_rxc>;
		pinctrl-13 = <&emac_rgmii_rx_ctl>;
		pinctrl-14 = <&emac_phy_vreg>;
		pinctrl-15 = <&emac_rgmii_vreg>;

		rx-fifo-depth = <16384>;
		tx-fifo-depth = <16384>;

		snps,mtl-rx-config = <&mtl_rx_setup>;
		snps,mtl-tx-config = <&mtl_tx_setup>;
		qcom,arm-smmu;
		qcom,phy-intr-redirect = <&tlmm 137 GPIO_ACTIVE_LOW>;
		snps,reset-gpios = <&tlmm 112 GPIO_ACTIVE_LOW>;
		snps,reset-delays-us = <0 10000 100000>;
		phy-mode = "rgmii";
		eth-c22-mdio-probe;
		ethqos_emb_smmu: ethqos_emb_smmu {
				compatible = "qcom,emac-smmu-embedded";
				iommus = <&apps_smmu 0x200 0xf>;
				qcom,iommu-dma = "fastmap";
				qcom,iommu-dma-addr-pool = <0x40000000 0x10000000>;
		};
	};
};

&firmware {
	qcom_scm {
		compatible = "qcom,scm";
		qcom,dload-mode = <&tcsr 0x13000>;
	};

	qtee_shmbridge {
		compatible = "qcom,tee-shared-memory-bridge";
	};

	qcom_smcinvoke {
		compatible = "qcom,smcinvoke";
	};
};

#include "pm2250-rpm-regulator.dtsi"
#include "sa410m-regulators.dtsi"
#include "scuba-thermal.dtsi"
#include "sa410m_auto-coresight.dtsi"

&thermal_zones {
	wlan {
		thermal-sensors = <&tsens0 1>;
	};

	cpuss-0 {
		thermal-sensors = <&tsens0 2>;
		trips {
			cpu-0-2-config {
				temperature = <115000>;
			};
		};
	};

	cpuss-1 {
		thermal-sensors = <&tsens0 3>;
		trips {
			cpu-1-3-config {
				temperature = <115000>;
			};
		};
	};

	mdm-0 {
		thermal-sensors = <&tsens0 4>;
		trips {
			mdm0-cx-mon {
				temperature = <105000>;
			};

			mdm0_emer_mon: mdm0-emer-mon {
				temperature = <125000>;
				hysteresis = <5000>;
				type = "passive";
			};
		};

		cooling-maps {
			/delete-node/ mdm0-cx-cdev0;
			/delete-node/ mdm0-cx-cdev2;

			mdm0-cx-cdev1 {
				cooling-device = <&modem_proc 1 1>;
			};

			mdm0-emer-cdev0 {
				trip = <&mdm0_emer_mon>;
				cooling-device = <&modem_proc 3 3>;
			};
		};
	};

	mdm-1 {
		thermal-sensors = <&tsens0 5>;
		trips {
			mdm1-cx-mon {
				temperature = <105000>;
			};

			mdm1_emer_mon: mdm1-emer-mon {
				temperature = <125000>;
				hysteresis = <5000>;
				type = "passive";
			};
		};

		cooling-maps {
			/delete-node/ mdm1-cx-cdev0;
			/delete-node/ mdm1-cx-cdev2;

			mdm1-cx-cdev1 {
				cooling-device = <&modem_proc 1 1>;
			};

			mdm1-emer-cdev0 {
				trip = <&mdm1_emer_mon>;
				cooling-device = <&modem_proc 3 3>;
			};
		};
	};

	video {
		thermal-sensors = <&tsens0 6>;
	};

	hm-center {
		thermal-sensors = <&tsens0 7>;
	};

	/delete-node/ gpu;
	/delete-node/ camera;
};

#include "sa410m-pmic.dtsi"
#include "msm-arm-smmu-sa410m.dtsi"
#include "sa410m-pinctrl.dtsi"
#include "sa410m-dma-heap.dtsi"
#include "monaco-gdsc.dtsi"
#include "sa410m-qupv3.dtsi"
#include "sa410m-usb.dtsi"
#include "sa410m-pcie.dtsi"
#include "sa410m-cnss.dtsi"

&gcc_emac0_gdsc {
	status = "ok";
};

&gcc_pcie_0_gdsc {
	status = "ok";
};

&gcc_usb30_prim_gdsc {
	status = "ok";
};

&hlos1_vote_mm_snoc_mmu_tbu_rt_gdsc {
	status = "ok";
};

&hlos1_vote_mm_snoc_mmu_tbu_nrt_gdsc {
	status = "ok";
};

&hlos1_vote_turing_mmu_tbu1_gdsc {
	status = "ok";
};

&hlos1_vote_turing_mmu_tbu0_gdsc {
	status = "ok";
};

&qupv3_se4_2uart {
	status = "ok";
};

&usb0 {
	USB3_GDSC-supply = <&gcc_usb30_prim_gdsc>;
};

&pm2250_l15 {
	regulator-always-on;
};

&pm2250_l17 {
	regulator-always-on;
};

&qupv3_se2_i2c {
	status = "okay";
	asm330lhh@6a {
		compatible = "st,asm330lhh";
		reg = <0x6a>;
		pinctrl-names = "default";
		pinctrl-0 = <&sensor_int1_default>,<&sensor_int2_default>;
		interrupt-parent = <&tlmm>;
		interrupts = <32 IRQ_TYPE_EDGE_RISING>;
		st,drdy-int-pin= <2>;
		qcom,regulator_check = <0>;
		qcom,asm330_hrtimer;
	};
};

&qusb_phy0 {
	extcon = <&pm2250_charger>;
};

&usb0 {
	extcon = <&qusb_phy0>;
};

&sdhc_2 {
	status = "disabled";

	vdd-supply = <&L21A>;
	qcom,vdd-voltage-level = <3075000 3075000>;
	qcom,vdd-current-level = <0 800000>;

	vdd-io-supply = <&L4A>;
	qcom,vdd-io-voltage-level = <1800000 2850000>;
	qcom,vdd-io-current-level = <0 22000>;


	pinctrl-names = "default", "sleep";
	pinctrl-0 = <&sdc2_on>;
	pinctrl-1 = <&sdc2_off>;

	cd-gpios = <&tlmm 88 GPIO_ACTIVE_LOW>;
};
